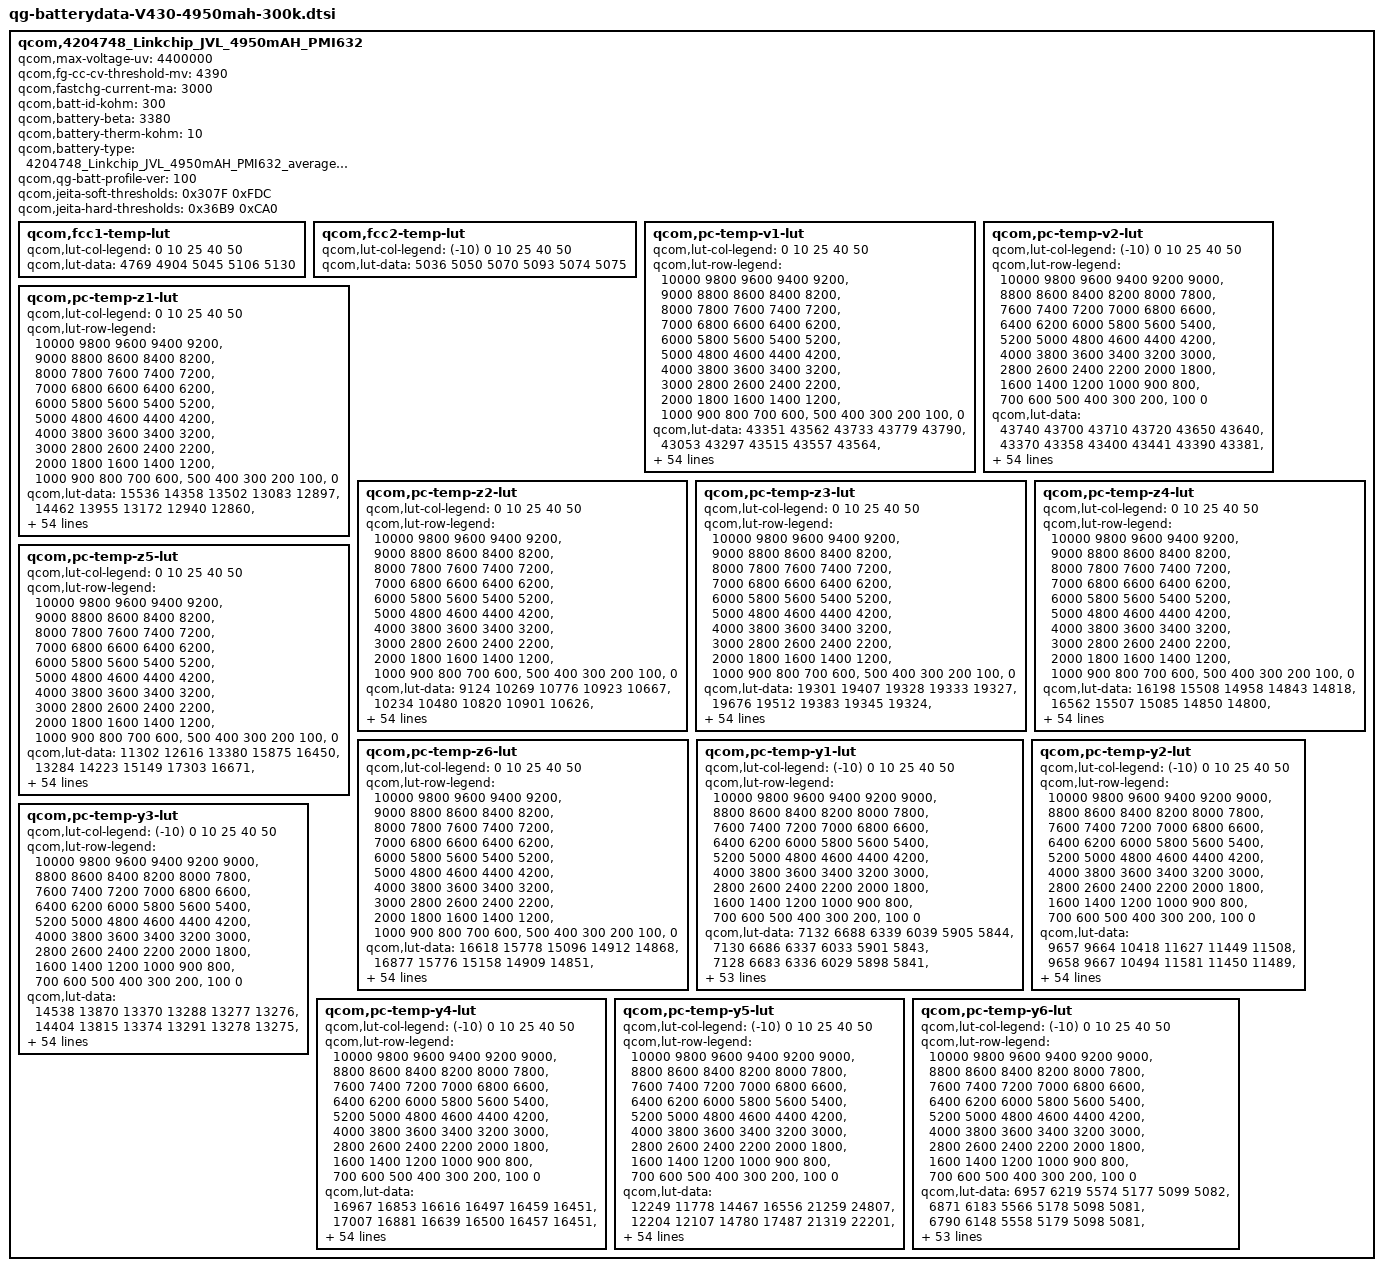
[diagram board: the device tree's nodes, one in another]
qcom,4204748_Linkchip_JVL_4950mAH_PMI632 {
    /* 4204748_Linkchip_JVL_4950mAH_PMI632_averaged_Master_Sep20th2019 */
    qcom,max-voltage-uv = <4400000>;
    qcom,fg-cc-cv-threshold-mv = <4390>;
    qcom,fastchg-current-ma = <3000>;
    qcom,batt-id-kohm = <300>;
    qcom,battery-beta = <3380>;
    qcom,battery-therm-kohm = <10>;
    qcom,battery-type = "4204748_Linkchip_JVL_4950mAH_PMI632_averaged_Master_Sep20th2019";
    qcom,qg-batt-profile-ver = <100>;
    /* COOL = 5 DegC, WARM = 45 DegC */
    qcom,jeita-soft-thresholds = <0x307F 0xFDC>;
    /* COLD = 0 DegC, HOT = 53 DegC */
    qcom,jeita-hard-thresholds = <0x36B9 0xCA0>;
	qcom,fcc1-temp-lut {
		qcom,lut-col-legend = <0 10 25 40 50>;
		qcom,lut-data = <4769 4904 5045 5106 5130>;
	};

	qcom,fcc2-temp-lut {
		qcom,lut-col-legend = <(-10) 0 10 25 40 50>;
		qcom,lut-data = <5036 5050 5070 5093 5074 5075>;
	};

	qcom,pc-temp-v1-lut {
		qcom,lut-col-legend = <0 10 25 40 50>;
		qcom,lut-row-legend = <10000 9800 9600 9400 9200>,
			<9000 8800 8600 8400 8200>,
			<8000 7800 7600 7400 7200>,
			<7000 6800 6600 6400 6200>,
			<6000 5800 5600 5400 5200>,
			<5000 4800 4600 4400 4200>,
			<4000 3800 3600 3400 3200>,
			<3000 2800 2600 2400 2200>,
			<2000 1800 1600 1400 1200>,
			<1000 900 800 700 600>,
			<500 400 300 200 100>,
			<0>;
		qcom,lut-data = <43351 43562 43733 43779 43790>,
			<43053 43297 43515 43557 43564>,
			<42798 43042 43276 43331 43342>,
			<42561 42799 43027 43097 43117>,
			<42328 42565 42786 42862 42888>,
			<42104 42335 42551 42629 42655>,
			<41887 42110 42319 42396 42420>,
			<41675 41893 42088 42165 42187>,
			<41472 41679 41860 41935 41958>,
			<41288 41472 41638 41709 41732>,
			<41132 41280 41420 41484 41506>,
			<40955 41113 41214 41266 41285>,
			<40699 40934 41031 41053 41071>,
			<40396 40693 40851 40850 40865>,
			<40160 40409 40631 40649 40663>,
			<39984 40184 40380 40453 40467>,
			<39834 40017 40171 40263 40277>,
			<39701 39871 40018 40086 40098>,
			<39583 39732 39878 39917 39926>,
			<39467 39603 39730 39751 39757>,
			<39347 39472 39580 39595 39597>,
			<39231 39336 39397 39420 39424>,
			<39121 39200 39145 39166 39192>,
			<39016 39065 38907 38901 38941>,
			<38918 38930 38744 38752 38783>,
			<38828 38799 38613 38659 38678>,
			<38743 38664 38522 38574 38584>,
			<38666 38543 38461 38486 38489>,
			<38595 38454 38406 38403 38400>,
			<38530 38382 38347 38326 38312>,
			<38467 38327 38292 38254 38228>,
			<38407 38288 38244 38188 38156>,
			<38353 38255 38202 38128 38098>,
			<38303 38223 38161 38071 38043>,
			<38257 38195 38119 38019 37985>,
			<38211 38163 38076 37969 37928>,
			<38165 38126 38033 37918 37868>,
			<38115 38083 37990 37868 37811>,
			<38056 38022 37933 37807 37742>,
			<37988 37934 37843 37721 37649>,
			<37904 37833 37731 37615 37539>,
			<37791 37714 37614 37502 37425>,
			<37660 37578 37484 37375 37299>,
			<37506 37416 37331 37225 37149>,
			<37359 37288 37184 37082 37011>,
			<37252 37192 37087 36989 36925>,
			<37215 37155 37059 36960 36898>,
			<37182 37129 37035 36942 36880>,
			<37149 37101 37018 36923 36858>,
			<37091 37051 36971 36864 36791>,
			<36887 36836 36740 36607 36522>,
			<36456 36410 36305 36175 36086>,
			<35900 35851 35747 35608 35519>,
			<35146 35096 34989 34841 34749>,
			<33965 33923 33823 33657 33563>,
			<30000 30000 30000 30000 30000>;
	};

	qcom,pc-temp-v2-lut {
		qcom,lut-col-legend = <(-10) 0 10 25 40 50>;
		qcom,lut-row-legend = <10000 9800 9600 9400 9200 9000>,
			<8800 8600 8400 8200 8000 7800>,
			<7600 7400 7200 7000 6800 6600>,
			<6400 6200 6000 5800 5600 5400>,
			<5200 5000 4800 4600 4400 4200>,
			<4000 3800 3600 3400 3200 3000>,
			<2800 2600 2400 2200 2000 1800>,
			<1600 1400 1200 1000 900 800>,
			<700 600 500 400 300 200>,
			<100 0>;
		qcom,lut-data = <43740 43700 43710 43720 43650 43640>,
			<43370 43358 43400 43441 43390 43381>,
			<43026 43038 43108 43175 43138 43130>,
			<42708 42739 42838 42924 42895 42888>,
			<42415 42460 42589 42687 42661 42654>,
			<42143 42195 42345 42453 42428 42423>,
			<41888 41943 42099 42219 42196 42193>,
			<41650 41702 41860 41988 41964 41965>,
			<41421 41461 41638 41760 41737 41739>,
			<41201 41220 41428 41536 41513 41515>,
			<41014 41046 41223 41315 41292 41294>,
			<40883 40953 41029 41096 41075 41077>,
			<40742 40853 40830 40884 40863 40864>,
			<40450 40575 40611 40691 40661 40660>,
			<39990 40093 40377 40506 40464 40461>,
			<39662 39764 40144 40307 40275 40270>,
			<39473 39581 39908 40089 40091 40088>,
			<39314 39422 39682 39887 39912 39911>,
			<39145 39248 39481 39722 39745 39744>,
			<38983 39075 39292 39565 39578 39577>,
			<38831 38912 39110 39366 39380 39382>,
			<38686 38757 38933 39119 39139 39148>,
			<38556 38615 38770 38905 38924 38937>,
			<38444 38485 38623 38739 38758 38768>,
			<38344 38367 38488 38597 38615 38622>,
			<38253 38270 38364 38478 38493 38498>,
			<38170 38187 38249 38375 38388 38391>,
			<38096 38117 38152 38280 38292 38293>,
			<38029 38055 38075 38191 38203 38202>,
			<37968 37999 38008 38107 38121 38119>,
			<37908 37945 37949 38030 38048 38045>,
			<37847 37893 37896 37957 37980 37977>,
			<37789 37842 37847 37889 37914 37910>,
			<37729 37792 37800 37825 37850 37848>,
			<37671 37742 37753 37765 37784 37780>,
			<37614 37692 37704 37708 37700 37684>,
			<37558 37640 37652 37651 37606 37569>,
			<37501 37580 37596 37589 37520 37469>,
			<37443 37510 37534 37520 37440 37382>,
			<37384 37432 37464 37445 37360 37299>,
			<37319 37345 37382 37364 37282 37218>,
			<37247 37249 37285 37269 37195 37131>,
			<37175 37156 37174 37149 37081 37019>,
			<37096 37066 37054 37024 36956 36892>,
			<37006 36978 36936 36906 36838 36784>,
			<36894 36890 36837 36849 36801 36747>,
			<36827 36837 36793 36826 36787 36738>,
			<36746 36789 36749 36796 36768 36721>,
			<36646 36723 36691 36761 36736 36691>,
			<36500 36605 36594 36661 36636 36576>,
			<36275 36389 36384 36357 36323 36250>,
			<35936 35988 35970 35868 35831 35759>,
			<35436 35389 35359 35210 35196 35120>,
			<34677 34533 34505 34285 34295 34222>,
			<33356 33093 33117 32789 33051 33018>,
			<30579 29742 30180 30095 29244 29314>;
	};

	qcom,pc-temp-z1-lut {
		qcom,lut-col-legend = <0 10 25 40 50>;
		qcom,lut-row-legend = <10000 9800 9600 9400 9200>,
			<9000 8800 8600 8400 8200>,
			<8000 7800 7600 7400 7200>,
			<7000 6800 6600 6400 6200>,
			<6000 5800 5600 5400 5200>,
			<5000 4800 4600 4400 4200>,
			<4000 3800 3600 3400 3200>,
			<3000 2800 2600 2400 2200>,
			<2000 1800 1600 1400 1200>,
			<1000 900 800 700 600>,
			<500 400 300 200 100>,
			<0>;
		qcom,lut-data = <15536 14358 13502 13083 12897>,
			<14462 13955 13172 12940 12860>,
			<14439 13735 13154 12924 12844>,
			<14431 13715 13141 12911 12834>,
			<14436 13706 13131 12901 12826>,
			<14454 13701 13122 12894 12822>,
			<14463 13699 13116 12888 12818>,
			<14437 13697 13111 12885 12818>,
			<14395 13692 13107 12882 12818>,
			<14376 13687 13105 12881 12818>,
			<14367 13684 13105 12881 12822>,
			<14357 13684 13105 12881 12828>,
			<14334 13683 13105 12884 12833>,
			<14301 13672 13104 12889 12838>,
			<14280 13648 13103 12892 12841>,
			<14266 13640 13097 12893 12843>,
			<14257 13642 13095 12894 12844>,
			<14253 13645 13099 12895 12846>,
			<14251 13649 13105 12898 12850>,
			<14248 13654 13110 12901 12852>,
			<14245 13660 13115 12903 12854>,
			<14241 13666 13120 12905 12856>,
			<14237 13672 13123 12907 12858>,
			<14233 13677 13126 12909 12861>,
			<14229 13682 13128 12912 12864>,
			<14226 13687 13132 12916 12867>,
			<14223 13694 13135 12921 12870>,
			<14221 13700 13138 12924 12874>,
			<14220 13702 13141 12928 12878>,
			<14219 13703 13145 12932 12882>,
			<14218 13705 13149 12937 12888>,
			<14216 13711 13152 12942 12893>,
			<14215 13718 13155 12946 12897>,
			<14216 13726 13159 12951 12901>,
			<14219 13733 13163 12955 12905>,
			<14224 13740 13168 12959 12909>,
			<14233 13747 13173 12964 12914>,
			<14245 13755 13178 12969 12918>,
			<14260 13762 13184 12974 12923>,
			<14275 13769 13191 12980 12928>,
			<14278 13775 13198 12986 12932>,
			<14277 13779 13204 12994 12936>,
			<14276 13782 13208 13003 12940>,
			<14280 13782 13213 13004 12945>,
			<14284 13790 13220 13005 12951>,
			<14283 13786 13228 13013 12955>,
			<14280 13791 13228 13014 12956>,
			<14279 13792 13229 13016 12957>,
			<14282 13789 13231 13017 12960>,
			<14284 13795 13235 13023 12967>,
			<14291 13814 13245 13032 12973>,
			<14307 13819 13257 13040 12982>,
			<14315 13840 13275 13054 12993>,
			<14339 13866 13304 13073 13011>,
			<14339 13866 13304 13073 13011>,
			<14339 13866 13304 13073 13011>;
	};

	qcom,pc-temp-z2-lut {
		qcom,lut-col-legend = <0 10 25 40 50>;
		qcom,lut-row-legend = <10000 9800 9600 9400 9200>,
			<9000 8800 8600 8400 8200>,
			<8000 7800 7600 7400 7200>,
			<7000 6800 6600 6400 6200>,
			<6000 5800 5600 5400 5200>,
			<5000 4800 4600 4400 4200>,
			<4000 3800 3600 3400 3200>,
			<3000 2800 2600 2400 2200>,
			<2000 1800 1600 1400 1200>,
			<1000 900 800 700 600>,
			<500 400 300 200 100>,
			<0>;
		qcom,lut-data = <9124 10269 10776 10923 10667>,
			<10234 10480 10820 10901 10626>,
			<10364 10587 10898 10981 10723>,
			<10414 10579 10932 10979 10749>,
			<10409 10555 10929 10975 10768>,
			<10380 10534 10882 10945 10814>,
			<10355 10510 10833 10891 10873>,
			<10341 10496 10804 10860 10881>,
			<10329 10495 10779 10840 10821>,
			<10323 10495 10756 10824 10768>,
			<10319 10496 10732 10815 10759>,
			<10315 10504 10722 10805 10752>,
			<10312 10511 10722 10775 10714>,
			<10307 10492 10723 10718 10597>,
			<10301 10446 10731 10697 10541>,
			<10286 10431 10760 10707 10548>,
			<10269 10439 10783 10723 10563>,
			<10252 10453 10795 10742 10587>,
			<10236 10475 10806 10764 10625>,
			<10224 10506 10821 10768 10654>,
			<10217 10516 10837 10759 10678>,
			<10211 10516 10844 10753 10690>,
			<10209 10515 10847 10795 10675>,
			<10208 10522 10849 10861 10648>,
			<10207 10544 10836 10838 10655>,
			<10208 10562 10811 10697 10716>,
			<10210 10573 10808 10627 10751>,
			<10191 10583 10838 10703 10734>,
			<9982 10606 10869 10808 10713>,
			<9775 10640 10886 10866 10750>,
			<9750 10655 10899 10910 10866>,
			<9743 10653 10901 10917 10896>,
			<9737 10651 10898 10871 10713>,
			<9731 10654 10896 10831 10550>,
			<9725 10666 10895 10836 10556>,
			<9721 10681 10895 10855 10581>,
			<9718 10702 10901 10878 10611>,
			<9715 10724 10927 10912 10651>,
			<9641 10740 10953 10948 10697>,
			<9517 10752 10976 10990 10761>,
			<9486 10766 10992 11024 10817>,
			<9521 10783 10993 11027 10819>,
			<9555 10802 10993 11022 10807>,
			<9577 10831 10997 11012 10801>,
			<9693 10538 11030 10974 10808>,
			<9712 10368 11107 10909 10839>,
			<9728 10684 11089 10924 10819>,
			<9743 21199 11091 10926 10841>,
			<9731 20713 11220 10941 10876>,
			<9721 19966 11241 11070 11059>,
			<9704 19206 11185 11093 10846>,
			<9605 10763 11141 10967 10631>,
			<9582 10300 11025 10840 10577>,
			<9404 10133 10894 10750 10527>,
			<9404 10133 10894 10750 10527>,
			<9404 10133 10894 10750 10527>;
	};

	qcom,pc-temp-z3-lut {
		qcom,lut-col-legend = <0 10 25 40 50>;
		qcom,lut-row-legend = <10000 9800 9600 9400 9200>,
			<9000 8800 8600 8400 8200>,
			<8000 7800 7600 7400 7200>,
			<7000 6800 6600 6400 6200>,
			<6000 5800 5600 5400 5200>,
			<5000 4800 4600 4400 4200>,
			<4000 3800 3600 3400 3200>,
			<3000 2800 2600 2400 2200>,
			<2000 1800 1600 1400 1200>,
			<1000 900 800 700 600>,
			<500 400 300 200 100>,
			<0>;
		qcom,lut-data = <19301 19407 19328 19333 19327>,
			<19676 19512 19383 19345 19324>,
			<19698 19578 19418 19367 19344>,
			<19705 19602 19444 19379 19350>,
			<19699 19617 19451 19385 19355>,
			<19676 19619 19453 19387 19361>,
			<19663 19613 19454 19387 19367>,
			<19664 19604 19454 19388 19369>,
			<19664 19594 19453 19388 19369>,
			<19666 19582 19451 19388 19369>,
			<19669 19569 19446 19387 19369>,
			<19674 19552 19441 19386 19369>,
			<19683 19541 19430 19382 19367>,
			<19696 19548 19420 19374 19359>,
			<19699 19567 19421 19369 19353>,
			<19684 19572 19429 19367 19350>,
			<19662 19558 19432 19365 19348>,
			<19643 19537 19419 19363 19345>,
			<19624 19517 19405 19362 19343>,
			<19605 19498 19404 19359 19340>,
			<19586 19492 19404 19356 19338>,
			<19566 19499 19406 19354 19336>,
			<19545 19510 19416 19356 19335>,
			<19523 19521 19425 19360 19334>,
			<19502 19534 19424 19358 19332>,
			<19485 19541 19422 19348 19323>,
			<19469 19546 19419 19343 19319>,
			<19451 19548 19414 19344 19324>,
			<19428 19547 19412 19345 19332>,
			<19407 19543 19413 19350 19345>,
			<19395 19538 19415 19360 19364>,
			<19387 19532 19415 19367 19370>,
			<19379 19523 19413 19372 19363>,
			<19370 19514 19412 19375 19355>,
			<19361 19502 19413 19373 19350>,
			<19356 19492 19415 19368 19345>,
			<19354 19482 19414 19363 19341>,
			<19351 19475 19409 19360 19338>,
			<19326 19476 19406 19357 19335>,
			<19286 19482 19405 19354 19334>,
			<19273 19486 19405 19352 19334>,
			<19272 19476 19403 19350 19334>,
			<19270 19466 19399 19347 19334>,
			<19269 19464 19397 19347 19335>,
			<19266 19350 19393 19345 19334>,
			<19265 19263 19377 19337 19327>,
			<19265 19261 19367 19337 19322>,
			<19265 19256 19365 19333 19318>,
			<19265 19256 19333 19325 19316>,
			<19265 19256 19326 19319 19304>,
			<19265 19256 19349 19320 19327>,
			<19267 19260 19354 19326 19335>,
			<19268 19262 19338 19334 19339>,
			<19274 19263 19335 19331 19341>,
			<19274 19263 19335 19331 19341>,
			<19274 19263 19335 19331 19341>;
	};

	qcom,pc-temp-z4-lut {
		qcom,lut-col-legend = <0 10 25 40 50>;
		qcom,lut-row-legend = <10000 9800 9600 9400 9200>,
			<9000 8800 8600 8400 8200>,
			<8000 7800 7600 7400 7200>,
			<7000 6800 6600 6400 6200>,
			<6000 5800 5600 5400 5200>,
			<5000 4800 4600 4400 4200>,
			<4000 3800 3600 3400 3200>,
			<3000 2800 2600 2400 2200>,
			<2000 1800 1600 1400 1200>,
			<1000 900 800 700 600>,
			<500 400 300 200 100>,
			<0>;
		qcom,lut-data = <16198 15508 14958 14843 14818>,
			<16562 15507 15085 14850 14800>,
			<16461 15505 15065 14895 14849>,
			<16305 15435 15006 14871 14836>,
			<16161 15282 14954 14842 14815>,
			<16003 15177 14903 14819 14798>,
			<15858 15107 14860 14797 14780>,
			<15732 15051 14828 14777 14764>,
			<15618 15005 14801 14758 14749>,
			<15513 14966 14780 14741 14736>,
			<15413 14932 14763 14726 14722>,
			<15332 14903 14747 14712 14710>,
			<15279 14876 14730 14702 14701>,
			<15237 14847 14716 14693 14693>,
			<15196 14820 14706 14685 14687>,
			<15153 14800 14698 14679 14680>,
			<15117 14786 14691 14673 14675>,
			<15094 14775 14684 14665 14669>,
			<15076 14771 14677 14658 14663>,
			<15069 14769 14670 14656 14661>,
			<15070 14764 14664 14658 14663>,
			<15071 14745 14666 14660 14665>,
			<15074 14725 14719 14713 14709>,
			<15082 14716 14775 14792 14783>,
			<15090 14709 14796 14803 14797>,
			<15094 14708 14809 14798 14793>,
			<15097 14723 14810 14790 14786>,
			<15103 14740 14793 14777 14770>,
			<15117 14741 14772 14760 14746>,
			<15128 14739 14757 14740 14721>,
			<15128 14736 14742 14718 14691>,
			<15124 14729 14728 14699 14676>,
			<15120 14721 14715 14681 14668>,
			<15114 14717 14703 14670 14664>,
			<15108 14714 14692 14668 14664>,
			<15097 14712 14684 14667 14664>,
			<15079 14710 14679 14667 14664>,
			<15068 14709 14675 14666 14664>,
			<15074 14704 14673 14666 14665>,
			<15084 14695 14680 14674 14673>,
			<15085 14691 14688 14684 14683>,
			<15068 14697 14687 14684 14682>,
			<15048 14702 14684 14680 14675>,
			<15030 14694 14681 14680 14677>,
			<14948 14781 14675 14679 14677>,
			<14927 14846 14658 14659 14657>,
			<14923 14844 14659 14652 14654>,
			<14919 14841 14652 14643 14642>,
			<14915 14833 14676 14635 14628>,
			<14906 14828 14680 14639 14637>,
			<14900 14836 14671 14664 14643>,
			<14941 14849 14676 14666 14647>,
			<14951 14862 14700 14662 14647>,
			<14974 14873 14710 14669 14648>,
			<14974 14873 14710 14669 14648>,
			<14974 14873 14710 14669 14648>;
	};

	qcom,pc-temp-z5-lut {
		qcom,lut-col-legend = <0 10 25 40 50>;
		qcom,lut-row-legend = <10000 9800 9600 9400 9200>,
			<9000 8800 8600 8400 8200>,
			<8000 7800 7600 7400 7200>,
			<7000 6800 6600 6400 6200>,
			<6000 5800 5600 5400 5200>,
			<5000 4800 4600 4400 4200>,
			<4000 3800 3600 3400 3200>,
			<3000 2800 2600 2400 2200>,
			<2000 1800 1600 1400 1200>,
			<1000 900 800 700 600>,
			<500 400 300 200 100>,
			<0>;
		qcom,lut-data = <11302 12616 13380 15875 16450>,
			<13284 14223 15149 17303 16671>,
			<13805 15416 16673 18524 18373>,
			<14138 16211 18295 19602 18827>,
			<14545 16798 19211 20414 19370>,
			<14943 17050 19716 20729 20159>,
			<15323 17180 20219 20954 21160>,
			<15690 17240 20977 21350 21910>,
			<16041 17233 21718 21993 22398>,
			<16359 17206 22091 22755 22965>,
			<16632 17158 22336 23905 24203>,
			<16947 17012 22420 24877 25519>,
			<17520 16893 22215 24949 25624>,
			<18196 18144 21959 24897 25213>,
			<18383 21072 24064 24938 25024>,
			<18152 22053 31126 26122 25831>,
			<17778 21461 34056 27964 27214>,
			<17345 20595 30775 30036 28646>,
			<16770 19705 27350 32408 30305>,
			<16200 18735 28040 33851 31616>,
			<15668 18507 31424 34644 32778>,
			<15154 20447 36980 35449 33396>,
			<14676 23946 52008 36865 32307>,
			<14214 29282 63690 38203 29567>,
			<13839 37666 59670 36348 26115>,
			<13596 44769 49228 27511 20924>,
			<13401 51050 41848 22111 18449>,
			<13158 55248 36157 20901 18494>,
			<12806 55282 33206 20299 18611>,
			<12515 53988 32968 20811 21114>,
			<12410 52042 32852 22884 28433>,
			<12353 47636 32874 25806 31538>,
			<12288 41908 33160 31366 31807>,
			<12194 37058 33691 36681 32065>,
			<12099 32375 37389 39772 33037>,
			<12035 29225 42090 42005 34391>,
			<11994 27215 42674 42259 34617>,
			<11936 25957 42360 41114 34037>,
			<11724 27047 41974 39387 33104>,
			<11435 31850 41605 36379 30921>,
			<11361 34461 41044 32572 28177>,
			<11403 30545 38848 29541 26590>,
			<11460 27290 34915 27060 25579>,
			<11535 28943 34056 26148 25565>,
			<11900 19772 34036 25893 25533>,
			<11937 12149 32430 25463 24114>,
			<11863 12101 26328 26119 22177>,
			<11849 11948 26100 25202 22661>,
			<11847 11959 18169 23935 25438>,
			<11865 11966 16454 21721 19681>,
			<11958 12024 20439 18320 22644>,
			<11933 11966 19545 17931 22703>,
			<11780 11840 16263 18695 22289>,
			<11684 11724 15403 17294 20429>,
			<11684 11724 15403 17294 20429>,
			<11684 11724 15403 17294 20429>;
	};

	qcom,pc-temp-z6-lut {
		qcom,lut-col-legend = <0 10 25 40 50>;
		qcom,lut-row-legend = <10000 9800 9600 9400 9200>,
			<9000 8800 8600 8400 8200>,
			<8000 7800 7600 7400 7200>,
			<7000 6800 6600 6400 6200>,
			<6000 5800 5600 5400 5200>,
			<5000 4800 4600 4400 4200>,
			<4000 3800 3600 3400 3200>,
			<3000 2800 2600 2400 2200>,
			<2000 1800 1600 1400 1200>,
			<1000 900 800 700 600>,
			<500 400 300 200 100>,
			<0>;
		qcom,lut-data = <16618 15778 15096 14912 14868>,
			<16877 15776 15158 14909 14851>,
			<16786 15770 15151 14934 14879>,
			<16651 15724 15126 14925 14874>,
			<16535 15630 15101 14914 14867>,
			<16418 15560 15071 14903 14862>,
			<16315 15509 15044 14893 14857>,
			<16234 15464 15024 14883 14852>,
			<16163 15423 15007 14874 14846>,
			<16100 15387 14992 14866 14840>,
			<16044 15354 14980 14859 14835>,
			<15994 15325 14967 14852 14831>,
			<15948 15300 14951 14845 14825>,
			<15907 15280 14938 14838 14819>,
			<15868 15263 14932 14832 14813>,
			<15830 15247 14930 14828 14809>,
			<15797 15230 14926 14824 14805>,
			<15774 15215 14916 14820 14801>,
			<15756 15203 14908 14816 14798>,
			<15741 15193 14907 14815 14797>,
			<15728 15189 14906 14814 14796>,
			<15717 15188 14908 14814 14796>,
			<15706 15187 14937 14838 14814>,
			<15695 15189 14967 14875 14846>,
			<15685 15195 14976 14880 14852>,
			<15676 15203 14982 14874 14847>,
			<15668 15216 14983 14868 14842>,
			<15660 15227 14975 14863 14838>,
			<15651 15228 14966 14858 14834>,
			<15643 15227 14962 14854 14831>,
			<15637 15225 14958 14850 14829>,
			<15632 15222 14953 14847 14826>,
			<15627 15217 14948 14843 14821>,
			<15620 15214 14944 14841 14815>,
			<15615 15211 14942 14838 14812>,
			<15613 15209 14941 14837 14810>,
			<15612 15209 14940 14835 14809>,
			<15612 15209 14939 14834 14808>,
			<15612 15211 14939 14834 14807>,
			<15612 15216 14945 14837 14811>,
			<15611 15220 14952 14841 14816>,
			<15604 15223 14953 14841 14816>,
			<15599 15225 14953 14840 14814>,
			<15599 15226 14954 14841 14816>,
			<15581 15221 14954 14841 14816>,
			<15573 15207 14944 14830 14805>,
			<15571 15209 14940 14828 14802>,
			<15570 15209 14938 14822 14795>,
			<15573 15206 14934 14815 14788>,
			<15575 15209 14934 14815 14788>,
			<15577 15224 14947 14829 14803>,
			<15608 15235 14958 14836 14812>,
			<15620 15255 14966 14842 14817>,
			<15658 15279 14979 14849 14822>,
			<15658 15279 14979 14849 14822>,
			<15658 15279 14979 14849 14822>;
	};

	qcom,pc-temp-y1-lut {
		qcom,lut-col-legend = <(-10) 0 10 25 40 50>;
		qcom,lut-row-legend = <10000 9800 9600 9400 9200 9000>,
			<8800 8600 8400 8200 8000 7800>,
			<7600 7400 7200 7000 6800 6600>,
			<6400 6200 6000 5800 5600 5400>,
			<5200 5000 4800 4600 4400 4200>,
			<4000 3800 3600 3400 3200 3000>,
			<2800 2600 2400 2200 2000 1800>,
			<1600 1400 1200 1000 900 800>,
			<700 600 500 400 300 200>,
			<100 0>;
		qcom,lut-data = <7132 6688 6339 6039 5905 5844>,
			<7130 6686 6337 6033 5901 5843>,
			<7128 6683 6336 6029 5898 5841>,
			<7127 6680 6334 6026 5895 5839>,
			<7125 6678 6332 6025 5892 5837>,
			<7124 6678 6332 6024 5889 5834>,
			<7124 6678 6332 6026 5886 5831>,
			<7123 6678 6332 6028 5884 5828>,
			<7123 6678 6332 6026 5881 5826>,
			<7122 6674 6330 6018 5877 5824>,
			<7121 6672 6329 6014 5875 5823>,
			<7121 6672 6331 6014 5874 5822>,
			<7121 6671 6333 6013 5873 5822>,
			<7123 6673 6334 6012 5871 5821>,
			<7127 6676 6335 6011 5870 5820>,
			<7128 6679 6337 6011 5869 5820>,
			<7128 6681 6341 6016 5870 5821>,
			<7127 6682 6344 6018 5870 5822>,
			<7127 6682 6344 6018 5871 5822>,
			<7127 6682 6343 6018 5872 5823>,
			<7127 6683 6343 6018 5873 5824>,
			<7127 6683 6343 6018 5874 5826>,
			<7127 6683 6343 6020 5874 5829>,
			<7127 6685 6344 6021 5876 5831>,
			<7127 6687 6346 6024 5879 5833>,
			<7127 6687 6347 6025 5881 5835>,
			<7127 6683 6347 6027 5883 5836>,
			<7127 6681 6348 6029 5886 5839>,
			<7126 6683 6348 6031 5889 5842>,
			<7124 6685 6349 6033 5892 5845>,
			<7125 6687 6350 6035 5895 5848>,
			<7129 6688 6352 6037 5899 5851>,
			<7132 6688 6353 6040 5903 5855>,
			<7132 6687 6356 6042 5906 5858>,
			<7132 6687 6358 6045 5909 5861>,
			<7132 6687 6359 6046 5911 5863>,
			<7132 6689 6360 6048 5913 5866>,
			<7133 6691 6360 6050 5916 5868>,
			<7136 6693 6361 6052 5919 5871>,
			<7139 6694 6361 6054 5922 5874>,
			<7139 6695 6363 6056 5927 5877>,
			<7138 6695 6365 6058 5930 5879>,
			<7139 6697 6366 6061 5930 5882>,
			<7143 6700 6367 6064 5932 5885>,
			<7157 6712 6374 6074 5938 5889>,
			<7162 6718 6377 6072 5942 5894>,
			<7166 6755 6379 6076 5943 5894>,
			<7210 6724 6383 6077 5945 5895>,
			<7193 6726 6385 6080 5945 5894>,
			<7221 6734 6387 6083 5945 5896>,
			<7204 6737 6395 6086 5950 5900>,
			<7203 6746 6404 6095 5959 5907>,
			<7240 6762 6420 6112 5970 5915>,
			<7300 6854 6444 6133 5986 5930>,
			<7300 6854 6444 6133 5986 5930>,
			<7300 6854 6444 6133 5986 5930>;
	};

	qcom,pc-temp-y2-lut {
		qcom,lut-col-legend = <(-10) 0 10 25 40 50>;
		qcom,lut-row-legend = <10000 9800 9600 9400 9200 9000>,
			<8800 8600 8400 8200 8000 7800>,
			<7600 7400 7200 7000 6800 6600>,
			<6400 6200 6000 5800 5600 5400>,
			<5200 5000 4800 4600 4400 4200>,
			<4000 3800 3600 3400 3200 3000>,
			<2800 2600 2400 2200 2000 1800>,
			<1600 1400 1200 1000 900 800>,
			<700 600 500 400 300 200>,
			<100 0>;
		qcom,lut-data = <9657 9664 10418 11627 11449 11508>,
			<9658 9667 10494 11581 11450 11489>,
			<9658 9670 10575 11535 11450 11452>,
			<9659 9674 10652 11492 11450 11410>,
			<9660 9677 10716 11456 11450 11375>,
			<9660 9681 10757 11430 11449 11362>,
			<9661 9686 10779 11414 11415 11361>,
			<9661 9691 10797 11400 11362 11361>,
			<9661 9695 10821 11387 11319 11325>,
			<9662 9699 10848 11373 11279 11218>,
			<9663 9721 10894 11363 11266 11173>,
			<9664 10055 11019 11354 11274 11171>,
			<9664 10399 11122 11349 11290 11170>,
			<9664 10261 11114 11368 11331 11198>,
			<9664 9850 11088 11418 11408 11272>,
			<9663 9701 11085 11467 11466 11328>,
			<9663 9696 11129 11518 11503 11365>,
			<9664 9692 11177 11565 11546 11405>,
			<9664 9689 11198 11610 11631 11475>,
			<9664 9686 11215 11644 11725 11547>,
			<9663 9684 11236 11637 11726 11545>,
			<9663 9684 11261 11588 11639 11468>,
			<9663 9683 11285 11565 11575 11422>,
			<9663 9683 11311 11647 11557 11446>,
			<9663 9682 11331 11741 11548 11487>,
			<9663 9682 11160 11746 11551 11511>,
			<9662 9682 10490 11737 11573 11529>,
			<9662 9681 10138 11735 11606 11551>,
			<9662 9679 10113 11747 11696 11590>,
			<9661 9676 10095 11760 11780 11626>,
			<9661 9674 10051 11762 11793 11645>,
			<9661 9672 9982 11763 11797 11659>,
			<9661 9670 9915 11763 11797 11662>,
			<9661 9669 9844 11762 11782 11659>,
			<9660 9667 9786 11760 11761 11657>,
			<9660 9666 9753 11756 11739 11665>,
			<9660 9665 9729 11747 11716 11679>,
			<9660 9664 9713 11729 11721 11679>,
			<9660 9662 9702 11688 11784 11655>,
			<9659 9662 9694 11635 11827 11622>,
			<9659 9661 9690 11566 11805 11572>,
			<9659 9660 9687 11495 11762 11539>,
			<9659 9659 9679 11434 11704 11559>,
			<9658 9659 9673 11396 11707 11591>,
			<9658 9659 9673 11307 11617 11522>,
			<9658 9658 9668 11285 11550 11381>,
			<9658 9658 9666 11195 11561 11367>,
			<9658 9657 9665 11148 11557 11456>,
			<9657 9657 9664 11160 11566 11441>,
			<9657 9657 9663 11152 11552 11423>,
			<9657 9657 9662 11054 11450 11272>,
			<9656 9656 9661 10921 11363 11211>,
			<9655 9656 9659 10798 11290 11107>,
			<9652 9655 9657 10659 11162 10945>,
			<9652 9655 9657 10659 11162 10945>,
			<9652 9655 9657 10659 11162 10945>;
	};

	qcom,pc-temp-y3-lut {
		qcom,lut-col-legend = <(-10) 0 10 25 40 50>;
		qcom,lut-row-legend = <10000 9800 9600 9400 9200 9000>,
			<8800 8600 8400 8200 8000 7800>,
			<7600 7400 7200 7000 6800 6600>,
			<6400 6200 6000 5800 5600 5400>,
			<5200 5000 4800 4600 4400 4200>,
			<4000 3800 3600 3400 3200 3000>,
			<2800 2600 2400 2200 2000 1800>,
			<1600 1400 1200 1000 900 800>,
			<700 600 500 400 300 200>,
			<100 0>;
		qcom,lut-data = <14538 13870 13370 13288 13277 13276>,
			<14404 13815 13374 13291 13278 13275>,
			<14273 13763 13379 13294 13280 13275>,
			<14152 13714 13382 13297 13281 13275>,
			<14047 13671 13385 13300 13282 13275>,
			<13966 13636 13385 13301 13283 13276>,
			<13909 13609 13384 13303 13282 13277>,
			<13860 13585 13383 13303 13282 13279>,
			<13794 13553 13384 13304 13282 13279>,
			<13714 13515 13390 13304 13282 13280>,
			<13684 13484 13391 13305 13282 13280>,
			<13692 13462 13381 13305 13282 13280>,
			<13701 13444 13368 13305 13281 13280>,
			<13678 13433 13365 13306 13283 13281>,
			<13609 13425 13362 13308 13286 13281>,
			<13578 13417 13359 13309 13289 13281>,
			<13573 13411 13355 13306 13290 13283>,
			<13570 13404 13350 13305 13290 13285>,
			<13571 13394 13345 13305 13290 13285>,
			<13574 13382 13340 13305 13290 13285>,
			<13575 13371 13336 13304 13288 13284>,
			<13575 13358 13333 13300 13285 13281>,
			<13574 13350 13329 13295 13282 13278>,
			<13578 13349 13326 13291 13280 13277>,
			<13586 13348 13322 13287 13279 13276>,
			<13595 13347 13309 13288 13278 13276>,
			<13606 13345 13276 13291 13278 13276>,
			<13620 13344 13261 13292 13278 13276>,
			<13639 13356 13261 13292 13278 13275>,
			<13662 13377 13261 13291 13278 13275>,
			<13686 13391 13262 13291 13278 13275>,
			<13710 13403 13263 13291 13279 13275>,
			<13735 13417 13264 13291 13279 13275>,
			<13761 13438 13268 13291 13280 13276>,
			<13789 13462 13273 13291 13281 13277>,
			<13821 13489 13281 13291 13280 13276>,
			<13856 13519 13294 13291 13278 13275>,
			<13895 13551 13307 13291 13278 13275>,
			<13938 13584 13322 13291 13278 13275>,
			<13982 13619 13331 13291 13278 13276>,
			<14024 13657 13331 13291 13278 13276>,
			<14065 13697 13331 13292 13278 13276>,
			<14116 13746 13374 13292 13278 13276>,
			<14171 13797 13406 13293 13278 13274>,
			<14172 13794 13405 13293 13275 13274>,
			<14225 13871 13456 13298 13280 13276>,
			<14282 13910 13488 13300 13282 13281>,
			<14344 13963 13520 13303 13287 13285>,
			<14410 14011 13552 13313 13290 13287>,
			<14480 14059 13590 13318 13290 13285>,
			<14561 14110 13626 13314 13285 13281>,
			<14702 14173 13674 13317 13286 13282>,
			<15062 14273 13763 13326 13291 13285>,
			<15747 14447 13895 13344 13296 13289>,
			<15747 14447 13895 13344 13296 13289>,
			<15747 14447 13895 13344 13296 13289>;
	};

	qcom,pc-temp-y4-lut {
		qcom,lut-col-legend = <(-10) 0 10 25 40 50>;
		qcom,lut-row-legend = <10000 9800 9600 9400 9200 9000>,
			<8800 8600 8400 8200 8000 7800>,
			<7600 7400 7200 7000 6800 6600>,
			<6400 6200 6000 5800 5600 5400>,
			<5200 5000 4800 4600 4400 4200>,
			<4000 3800 3600 3400 3200 3000>,
			<2800 2600 2400 2200 2000 1800>,
			<1600 1400 1200 1000 900 800>,
			<700 600 500 400 300 200>,
			<100 0>;
		qcom,lut-data = <16967 16853 16616 16497 16459 16451>,
			<17007 16881 16639 16500 16457 16451>,
			<17058 16930 16674 16504 16456 16451>,
			<17108 16984 16713 16507 16456 16451>,
			<17145 17026 16743 16510 16456 16451>,
			<17158 17041 16757 16511 16456 16451>,
			<17150 17038 16760 16512 16458 16452>,
			<17140 17034 16762 16513 16463 16453>,
			<17159 17040 16765 16515 16467 16455>,
			<17231 17068 16768 16520 16471 16459>,
			<17266 17107 16776 16527 16476 16463>,
			<17266 17194 16829 16534 16483 16466>,
			<17266 17268 16878 16544 16489 16470>,
			<17194 17174 16875 16560 16494 16475>,
			<16988 16918 16858 16583 16498 16481>,
			<16899 16828 16833 16602 16504 16488>,
			<16892 16827 16777 16617 16515 16495>,
			<16886 16825 16724 16630 16530 16503>,
			<16869 16812 16696 16645 16555 16522>,
			<16842 16783 16674 16657 16582 16544>,
			<16822 16757 16647 16640 16578 16543>,
			<16805 16731 16615 16559 16527 16512>,
			<16793 16709 16588 16505 16486 16483>,
			<16785 16690 16568 16488 16466 16464>,
			<16778 16676 16555 16480 16454 16451>,
			<16778 16675 16564 16479 16453 16450>,
			<16780 16682 16603 16479 16455 16451>,
			<16782 16686 16623 16479 16458 16454>,
			<16778 16681 16622 16483 16464 16459>,
			<16773 16675 16621 16489 16472 16467>,
			<16772 16676 16623 16494 16482 16475>,
			<16778 16684 16630 16498 16492 16485>,
			<16785 16691 16632 16499 16499 16493>,
			<16792 16695 16631 16498 16503 16503>,
			<16800 16699 16630 16497 16505 16508>,
			<16808 16703 16632 16495 16495 16496>,
			<16818 16707 16638 16494 16475 16470>,
			<16829 16710 16644 16492 16465 16460>,
			<16843 16715 16648 16491 16460 16456>,
			<16860 16717 16655 16491 16458 16455>,
			<16879 16714 16688 16498 16465 16460>,
			<16900 16707 16718 16505 16471 16466>,
			<16919 16704 16681 16508 16469 16464>,
			<16926 16702 16670 16506 16463 16455>,
			<16865 16686 16646 16490 16449 16440>,
			<16842 16701 16669 16507 16460 16458>,
			<16853 16722 16693 16527 16477 16476>,
			<16872 16748 16735 16557 16497 16501>,
			<16887 16781 16787 16604 16530 16534>,
			<16906 16816 16817 16634 16536 16526>,
			<16911 16820 16833 16590 16491 16472>,
			<16928 16791 16818 16584 16479 16464>,
			<17036 16790 16819 16603 16489 16469>,
			<17327 16827 16856 16643 16512 16487>,
			<17327 16827 16856 16643 16512 16487>,
			<17327 16827 16856 16643 16512 16487>;
	};

	qcom,pc-temp-y5-lut {
		qcom,lut-col-legend = <(-10) 0 10 25 40 50>;
		qcom,lut-row-legend = <10000 9800 9600 9400 9200 9000>,
			<8800 8600 8400 8200 8000 7800>,
			<7600 7400 7200 7000 6800 6600>,
			<6400 6200 6000 5800 5600 5400>,
			<5200 5000 4800 4600 4400 4200>,
			<4000 3800 3600 3400 3200 3000>,
			<2800 2600 2400 2200 2000 1800>,
			<1600 1400 1200 1000 900 800>,
			<700 600 500 400 300 200>,
			<100 0>;
		qcom,lut-data = <12249 11778 14467 16556 21259 24807>,
			<12204 12107 14780 17487 21319 22201>,
			<12242 12435 15516 18480 21355 20398>,
			<12347 12740 16381 19371 21373 19274>,
			<12504 12999 17081 19995 21379 18705>,
			<12699 13190 17327 20190 21359 18578>,
			<13033 13347 17324 20055 20093 19374>,
			<13333 13449 17321 19777 18255 20332>,
			<13282 13311 17774 19293 17334 20059>,
			<12988 12825 19164 18451 16722 18800>,
			<12976 12743 19612 17691 16124 17822>,
			<16771 15816 17690 16960 15382 17249>,
			<20965 19032 15821 16469 14903 16762>,
			<19528 17991 17199 16335 15249 16214>,
			<14580 14805 20557 16260 16064 15706>,
			<12710 13721 21532 16257 16284 15614>,
			<12891 13900 21299 16356 16158 15868>,
			<13117 14078 21116 16550 16061 16093>,
			<13253 14123 21277 18256 16298 16135>,
			<13361 14149 21618 21043 16953 16162>,
			<13357 14140 21857 22630 18258 16678>,
			<13051 14007 22056 23778 21339 19244>,
			<12737 13802 22142 24128 23024 21371>,
			<12629 13475 21718 21445 22558 22366>,
			<12555 13044 20725 18350 21736 22983>,
			<12431 12689 18652 18915 21089 22730>,
			<12208 12349 14426 21270 20487 21425>,
			<12078 12200 12538 22201 20005 20182>,
			<12244 12461 12550 22269 19572 19040>,
			<12507 12816 12562 22297 19300 18266>,
			<12546 12830 12525 22297 19364 18230>,
			<12491 12704 12418 22296 19668 18262>,
			<12424 12645 12397 22341 20201 18448>,
			<12341 12743 12664 22650 21768 20024>,
			<12268 12927 12992 22864 22975 21360>,
			<12271 13212 13162 22823 22748 21320>,
			<12330 13628 13299 22711 22194 21185>,
			<12410 13771 13528 22414 21894 21222>,
			<12563 13730 13981 21555 21775 21683>,
			<12698 13657 14260 20634 21595 21996>,
			<12700 13512 13528 19770 20622 21004>,
			<12677 13355 12749 18989 19694 20058>,
			<12831 13383 13686 18300 19508 20570>,
			<13090 13423 13708 18552 20221 19432>,
			<13277 13250 13310 18816 17814 19046>,
			<13389 13383 13561 18479 18790 16868>,
			<13627 13098 13748 17663 18148 18477>,
			<13738 13518 14013 17097 18920 18900>,
			<14100 13894 14144 18262 18971 18276>,
			<14084 13852 15079 19017 18783 17639>,
			<14022 14179 15223 18378 17926 17492>,
			<13685 13827 14573 18528 19549 18897>,
			<12754 13108 13651 17963 21497 19254>,
			<11490 13072 13040 18215 22286 22452>,
			<11490 13072 13040 18215 22286 22452>,
			<11490 13072 13040 18215 22286 22452>;
	};

	qcom,pc-temp-y6-lut {
		qcom,lut-col-legend = <(-10) 0 10 25 40 50>;
		qcom,lut-row-legend = <10000 9800 9600 9400 9200 9000>,
			<8800 8600 8400 8200 8000 7800>,
			<7600 7400 7200 7000 6800 6600>,
			<6400 6200 6000 5800 5600 5400>,
			<5200 5000 4800 4600 4400 4200>,
			<4000 3800 3600 3400 3200 3000>,
			<2800 2600 2400 2200 2000 1800>,
			<1600 1400 1200 1000 900 800>,
			<700 600 500 400 300 200>,
			<100 0>;
		qcom,lut-data = <6957 6219 5574 5177 5099 5082>,
			<6871 6183 5566 5178 5098 5081>,
			<6790 6148 5558 5179 5098 5081>,
			<6715 6115 5550 5179 5097 5081>,
			<6646 6083 5541 5178 5097 5081>,
			<6586 6052 5531 5178 5097 5082>,
			<6533 6023 5520 5176 5097 5083>,
			<6486 5994 5510 5174 5098 5084>,
			<6445 5963 5502 5173 5098 5085>,
			<6407 5930 5494 5173 5099 5086>,
			<6388 5919 5491 5173 5100 5087>,
			<6384 5932 5491 5174 5101 5088>,
			<6379 5946 5491 5176 5103 5089>,
			<6340 5909 5487 5180 5105 5091>,
			<6246 5809 5475 5186 5108 5093>,
			<6202 5769 5462 5191 5112 5095>,
			<6194 5765 5445 5195 5116 5098>,
			<6189 5761 5428 5198 5120 5102>,
			<6183 5753 5415 5201 5127 5108>,
			<6178 5742 5404 5204 5134 5114>,
			<6174 5734 5393 5198 5132 5113>,
			<6170 5726 5382 5172 5115 5101>,
			<6168 5721 5374 5154 5101 5091>,
			<6170 5722 5370 5146 5094 5084>,
			<6174 5724 5366 5142 5090 5081>,
			<6180 5726 5365 5142 5090 5080>,
			<6190 5732 5364 5145 5091 5081>,
			<6202 5740 5364 5147 5092 5082>,
			<6215 5754 5370 5150 5094 5083>,
			<6230 5773 5379 5153 5097 5085>,
			<6248 5791 5388 5155 5100 5088>,
			<6270 5809 5400 5157 5103 5091>,
			<6294 5829 5414 5159 5106 5094>,
			<6316 5851 5430 5161 5109 5098>,
			<6339 5875 5449 5163 5110 5100>,
			<6364 5903 5468 5164 5107 5096>,
			<6393 5933 5490 5166 5101 5088>,
			<6425 5965 5514 5168 5099 5086>,
			<6463 5997 5542 5170 5098 5086>,
			<6503 6031 5572 5172 5098 5086>,
			<6541 6062 5604 5178 5100 5088>,
			<6580 6095 5639 5184 5102 5090>,
			<6625 6136 5676 5190 5103 5090>,
			<6672 6179 5714 5197 5102 5087>,
			<6670 6179 5714 5195 5097 5083>,
			<6710 6244 5778 5212 5105 5090>,
			<6761 6282 5816 5224 5112 5099>,
			<6819 6330 5863 5241 5121 5110>,
			<6876 6379 5905 5266 5133 5120>,
			<6936 6430 5945 5286 5135 5117>,
			<7005 6472 5988 5275 5119 5099>,
			<7142 6518 6033 5288 5118 5098>,
			<7510 6602 6122 5325 5128 5103>,
			<8212 6765 6249 5379 5141 5114>,
			<8212 6765 6249 5379 5141 5114>,
			<8212 6765 6249 5379 5141 5114>;
	};

};
